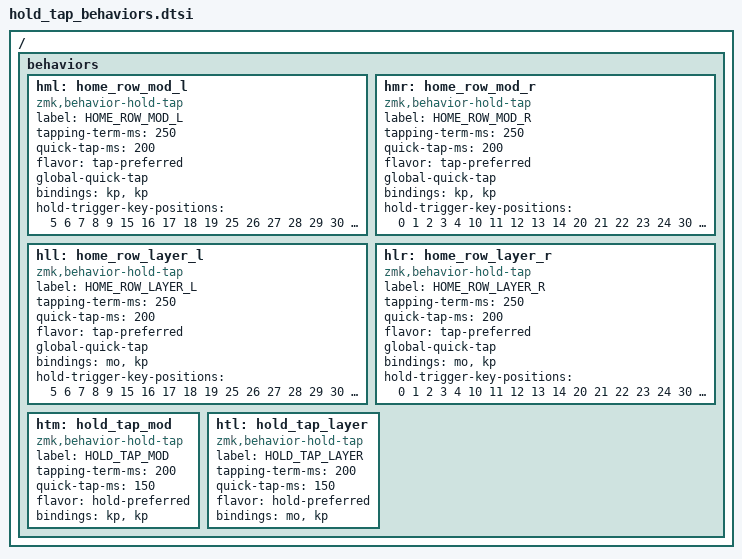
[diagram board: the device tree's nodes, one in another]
#include <behaviors.dtsi>

/ {
  behaviors {
      hml: home_row_mod_l {
        compatible = "zmk,behavior-hold-tap";
        label = "HOME_ROW_MOD_L";
        #binding-cells = <2>;
        tapping-term-ms = <250>;
        quick-tap-ms = <200>;
        flavor = "tap-preferred";
        global-quick-tap;
        bindings = <&kp>, <&kp>;
        hold-trigger-key-positions = <5 6 7 8 9 15 16 17 18 19 25 26 27 28 29 30 31 32 33 34 35 36 37 38 39 40 41>;
      };
      hmr: home_row_mod_r {
        compatible = "zmk,behavior-hold-tap";
        label = "HOME_ROW_MOD_R";
        #binding-cells = <2>;
        tapping-term-ms = <250>;
        quick-tap-ms = <200>;
        flavor = "tap-preferred";
        global-quick-tap;
        bindings = <&kp>, <&kp>;
        hold-trigger-key-positions = <0 1 2 3 4 10 11 12 13 14 20 21 22 23 24 30 31 32 33 34 35 36 37 38 39 40 41>;
      };
      hll: home_row_layer_l {
        compatible = "zmk,behavior-hold-tap";
        label = "HOME_ROW_LAYER_L";
        #binding-cells = <2>;
        tapping-term-ms = <250>;
        quick-tap-ms = <200>;
        flavor = "tap-preferred";
        global-quick-tap;
        bindings = <&mo>, <&kp>;
        hold-trigger-key-positions = <5 6 7 8 9 15 16 17 18 19 25 26 27 28 29 30 31 32 33 34 35 36 37 38 39 40 41>;
      };
      hlr: home_row_layer_r {
        compatible = "zmk,behavior-hold-tap";
        label = "HOME_ROW_LAYER_R";
        #binding-cells = <2>;
        tapping-term-ms = <250>;
        quick-tap-ms = <200>;
        flavor = "tap-preferred";
        global-quick-tap;
        bindings = <&mo>, <&kp>;
        hold-trigger-key-positions = <0 1 2 3 4 10 11 12 13 14 20 21 22 23 24 30 31 32 33 34 35 36 37 38 39 40 41>;
      };
      htm: hold_tap_mod {
        compatible = "zmk,behavior-hold-tap";
        label = "HOLD_TAP_MOD";
        #binding-cells = <2>;
        tapping-term-ms = <200>;
        quick-tap-ms = <150>;
        flavor = "hold-preferred";
        bindings = <&kp>, <&kp>;
      };
      htl: hold_tap_layer {
        compatible = "zmk,behavior-hold-tap";
        label = "HOLD_TAP_LAYER";
        #binding-cells = <2>;
        tapping-term-ms = <200>;
        quick-tap-ms = <150>;
        flavor = "hold-preferred";
        bindings = <&mo>, <&kp>;
      };
  };
};
